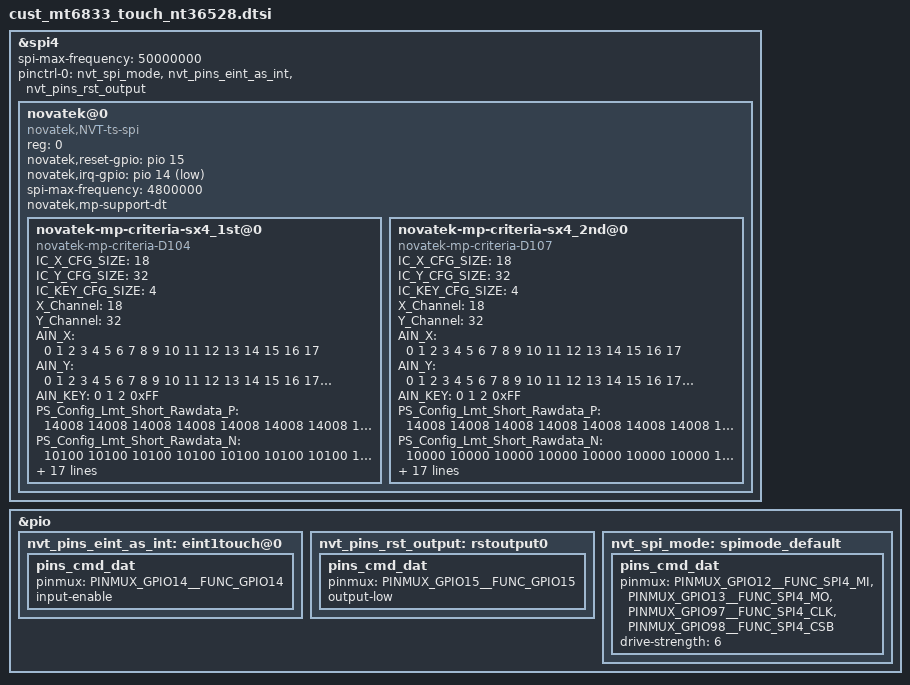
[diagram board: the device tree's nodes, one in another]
&spi4 {
    status = "okay";
	spi-max-frequency = <50000000>;
	pinctrl-names = "nvt_spi_mode";
	pinctrl-0 = <&nvt_spi_mode>,<&nvt_pins_eint_as_int>,<&nvt_pins_rst_output>;
	novatek@0 {
        status = "okay";
		compatible = "novatek,NVT-ts-spi";
		reg = <0>; //Same as CS ID
		novatek,reset-gpio = <&pio 15 0x00>;
		novatek,irq-gpio = <&pio 14 0x2001>;	
		spi-max-frequency = <4800000>;	//4800000,9600000,15000000,19200000

		novatek,mp-support-dt;

		novatek-mp-criteria-sx4_1st@0 {
			#address-cells = <1>;
			#size-cells = <0>;
			compatible = "novatek-mp-criteria-D104";

			/* MP Config */
			IC_X_CFG_SIZE = <18>;
			IC_Y_CFG_SIZE = <32>;
			IC_KEY_CFG_SIZE = <4>;
			X_Channel = <18>;
			Y_Channel = <32>;
			AIN_X = <0 1 2 3 4 5 6 7 8 9 10 11 12 13 14 15 16 17>;
			AIN_Y = <0 1 2 3 4 5 6 7 8 9 10 11 12 13 14 15 16 17 18 19 20 21 22 23 24 25 26 27 28 29 30 31>;
			AIN_KEY = <0 1 2 0xFF>;

			/* MP Criteria */
			PS_Config_Lmt_Short_Rawdata_P = <
				14008	14008	14008	14008	14008	14008	14008	14008	14008	14008	14008	14008	14008	14008	14008	14008	14008	14008
				14008	14008	14008	14008	14008	14008	14008	14008	14008	14008	14008	14008	14008	14008	14008	14008	14008	14008
				14008	14008	14008	14008	14008	14008	14008	14008	14008	14008	14008	14008	14008	14008	14008	14008	14008	14008
				14008	14008	14008	14008	14008	14008	14008	14008	14008	14008	14008	14008	14008	14008	14008	14008	14008	14008
				14008	14008	14008	14008	14008	14008	14008	14008	14008	14008	14008	14008	14008	14008	14008	14008	14008	14008
				14008	14008	14008	14008	14008	14008	14008	14008	14008	14008	14008	14008	14008	14008	14008	14008	14008	14008
				14008	14008	14008	14008	14008	14008	14008	14008	14008	14008	14008	14008	14008	14008	14008	14008	14008	14008
				14008	14008	14008	14008	14008	14008	14008	14008	14008	14008	14008	14008	14008	14008	14008	14008	14008	14008
				14008	14008	14008	14008	14008	14008	14008	14008	14008	14008	14008	14008	14008	14008	14008	14008	14008	14008
				14008	14008	14008	14008	14008	14008	14008	14008	14008	14008	14008	14008	14008	14008	14008	14008	14008	14008
				14008	14008	14008	14008	14008	14008	14008	14008	14008	14008	14008	14008	14008	14008	14008	14008	14008	14008
				14008	14008	14008	14008	14008	14008	14008	14008	14008	14008	14008	14008	14008	14008	14008	14008	14008	14008
				14008	14008	14008	14008	14008	14008	14008	14008	14008	14008	14008	14008	14008	14008	14008	14008	14008	14008
				14008	14008	14008	14008	14008	14008	14008	14008	14008	14008	14008	14008	14008	14008	14008	14008	14008	14008
				14008	14008	14008	14008	14008	14008	14008	14008	14008	14008	14008	14008	14008	14008	14008	14008	14008	14008
				14008	14008	14008	14008	14008	14008	14008	14008	14008	14008	14008	14008	14008	14008	14008	14008	14008	14008
				14008	14008	14008	14008	14008	14008	14008	14008	14008	14008	14008	14008	14008	14008	14008	14008	14008	14008
				14008	14008	14008	14008	14008	14008	14008	14008	14008	14008	14008	14008	14008	14008	14008	14008	14008	14008
				14008	14008	14008	14008	14008	14008	14008	14008	14008	14008	14008	14008	14008	14008	14008	14008	14008	14008
				14008	14008	14008	14008	14008	14008	14008	14008	14008	14008	14008	14008	14008	14008	14008	14008	14008	14008
				14008	14008	14008	14008	14008	14008	14008	14008	14008	14008	14008	14008	14008	14008	14008	14008	14008	14008
				14008	14008	14008	14008	14008	14008	14008	14008	14008	14008	14008	14008	14008	14008	14008	14008	14008	14008
				14008	14008	14008	14008	14008	14008	14008	14008	14008	14008	14008	14008	14008	14008	14008	14008	14008	14008
				14008	14008	14008	14008	14008	14008	14008	14008	14008	14008	14008	14008	14008	14008	14008	14008	14008	14008
				14008	14008	14008	14008	14008	14008	14008	14008	14008	14008	14008	14008	14008	14008	14008	14008	14008	14008
				14008	14008	14008	14008	14008	14008	14008	14008	14008	14008	14008	14008	14008	14008	14008	14008	14008	14008
				14008	14008	14008	14008	14008	14008	14008	14008	14008	14008	14008	14008	14008	14008	14008	14008	14008	14008
				14008	14008	14008	14008	14008	14008	14008	14008	14008	14008	14008	14008	14008	14008	14008	14008	14008	14008
				14008	14008	14008	14008	14008	14008	14008	14008	14008	14008	14008	14008	14008	14008	14008	14008	14008	14008
				14008	14008	14008	14008	14008	14008	14008	14008	14008	14008	14008	14008	14008	14008	14008	14008	14008	14008
				14008	14008	14008	14008	14008	14008	14008	14008	14008	14008	14008	14008	14008	14008	14008	14008	14008	14008
				14008	14008	14008	14008	14008	14008	14008	14008	14008	14008	14008	14008	14008	14008	14008	14008	14008	14008
				>;

			PS_Config_Lmt_Short_Rawdata_N = <
				10100	10100	10100	10100	10100	10100	10100	10100	10100	10100	10100	10100	10100	10100	10100	10100	10100	10100
				10100	10100	10100	10100	10100	10100	10100	10100	10100	10100	10100	10100	10100	10100	10100	10100	10100	10100
				10100	10100	10100	10100	10100	10100	10100	10100	10100	10100	10100	10100	10100	10100	10100	10100	10100	10100
				10100	10100	10100	10100	10100	10100	10100	10100	10100	10100	10100	10100	10100	10100	10100	10100	10100	10100
				10100	10100	10100	10100	10100	10100	10100	10100	10100	10100	10100	10100	10100	10100	10100	10100	10100	10100
				10100	10100	10100	10100	10100	10100	10100	10100	10100	10100	10100	10100	10100	10100	10100	10100	10100	10100
				10100	10100	10100	10100	10100	10100	10100	10100	10100	10100	10100	10100	10100	10100	10100	10100	10100	10100
				10100	10100	10100	10100	10100	10100	10100	10100	10100	10100	10100	10100	10100	10100	10100	10100	10100	10100
				10100	10100	10100	10100	10100	10100	10100	10100	10100	10100	10100	10100	10100	10100	10100	10100	10100	10100
				10100	10100	10100	10100	10100	10100	10100	10100	10100	10100	10100	10100	10100	10100	10100	10100	10100	10100
				10100	10100	10100	10100	10100	10100	10100	10100	10100	10100	10100	10100	10100	10100	10100	10100	10100	10100
				10100	10100	10100	10100	10100	10100	10100	10100	10100	10100	10100	10100	10100	10100	10100	10100	10100	10100
				10100	10100	10100	10100	10100	10100	10100	10100	10100	10100	10100	10100	10100	10100	10100	10100	10100	10100
				10100	10100	10100	10100	10100	10100	10100	10100	10100	10100	10100	10100	10100	10100	10100	10100	10100	10100
				10100	10100	10100	10100	10100	10100	10100	10100	10100	10100	10100	10100	10100	10100	10100	10100	10100	10100
				10100	10100	10100	10100	10100	10100	10100	10100	10100	10100	10100	10100	10100	10100	10100	10100	10100	10100
				10100	10100	10100	10100	10100	10100	10100	10100	10100	10100	10100	10100	10100	10100	10100	10100	10100	10100
				10100	10100	10100	10100	10100	10100	10100	10100	10100	10100	10100	10100	10100	10100	10100	10100	10100	10100
				10100	10100	10100	10100	10100	10100	10100	10100	10100	10100	10100	10100	10100	10100	10100	10100	10100	10100
				10100	10100	10100	10100	10100	10100	10100	10100	10100	10100	10100	10100	10100	10100	10100	10100	10100	10100
				10100	10100	10100	10100	10100	10100	10100	10100	10100	10100	10100	10100	10100	10100	10100	10100	10100	10100
				10100	10100	10100	10100	10100	10100	10100	10100	10100	10100	10100	10100	10100	10100	10100	10100	10100	10100
				10100	10100	10100	10100	10100	10100	10100	10100	10100	10100	10100	10100	10100	10100	10100	10100	10100	10100
				10100	10100	10100	10100	10100	10100	10100	10100	10100	10100	10100	10100	10100	10100	10100	10100	10100	10100
				10100	10100	10100	10100	10100	10100	10100	10100	10100	10100	10100	10100	10100	10100	10100	10100	10100	10100
				10100	10100	10100	10100	10100	10100	10100	10100	10100	10100	10100	10100	10100	10100	10100	10100	10100	10100
				10100	10100	10100	10100	10100	10100	10100	10100	10100	10100	10100	10100	10100	10100	10100	10100	10100	10100
				10100	10100	10100	10100	10100	10100	10100	10100	10100	10100	10100	10100	10100	10100	10100	10100	10100	10100
				10100	10100	10100	10100	10100	10100	10100	10100	10100	10100	10100	10100	10100	10100	10100	10100	10100	10100
				10100	10100	10100	10100	10100	10100	10100	10100	10100	10100	10100	10100	10100	10100	10100	10100	10100	10100
				10100	10100	10100	10100	10100	10100	10100	10100	10100	10100	10100	10100	10100	10100	10100	10100	10100	10100
				10100	10100	10100	10100	10100	10100	10100	10100	10100	10100	10100	10100	10100	10100	10100	10100	10100	10100
				>;

			PS_Config_Lmt_Open_Rawdata_P = <
				2699	2673	2589	2537	2470	2404	2369	2297	65535	65535	2071	2139	2159	2209	2255	2272	2331	2388
				2590	2594	2537	2468	2407	2355	2311	2279	2244	2332	2356	2381	2411	2449	2486	2519	2570	2619
				2800	2808	2752	2688	2628	2572	2528	2496	2463	2216	2234	2253	2288	2324	2358	2390	2436	2484
				2633	2657	2604	2538	2477	2425	2383	2349	2320	2379	2397	2419	2456	2492	2530	2566	2614	2661
				2782	2813	2750	2685	2619	2561	2519	2482	2456	2307	2327	2344	2377	2415	2450	2484	2530	2575
				2688	2730	2667	2603	2541	2486	2444	2408	2380	2475	2493	2514	2549	2590	2629	2670	2719	2762
				2806	2772	2724	2666	2596	2537	2503	2463	2423	2335	2359	2387	2411	2457	2498	2526	2569	2510
				2667	2628	2587	2530	2463	2404	2373	2334	2300	2519	2542	2575	2598	2649	2695	2727	2768	2727
				2870	2828	2782	2726	2656	2594	2565	2520	2486	2442	2467	2492	2517	2561	2605	2633	2674	2639
				2733	2688	2645	2586	2517	2457	2426	2383	2351	2572	2596	2628	2653	2699	2745	2782	2822	2801
				2975	2925	2873	2815	2745	2685	2647	2608	2572	2481	2502	2533	2552	2598	2647	2671	2717	2705
				2842	2790	2741	2682	2615	2558	2524	2484	2449	2727	2754	2786	2810	2856	2904	2934	2983	2982
				3060	3006	2953	2891	2827	2765	2726	2688	2643	2593	2615	2647	2667	2715	2759	2782	2829	2838
				2947	2901	2843	2780	2715	2654	2617	2580	2540	2705	2733	2762	2786	2834	2878	2909	2961	2976
				3156	3102	3042	2985	2916	2855	2822	2778	2740	2617	2646	2673	2702	2747	2790	2818	2869	2897
				3032	2982	2926	2866	2799	2740	2703	2661	2626	2797	2825	2855	2887	2932	2978	3016	3066	3102
				3259	3205	3143	3086	3016	2951	2915	2866	2832	2747	2773	2804	2828	2873	2915	2944	2995	3039
				3140	3087	3031	2969	2899	2841	2803	2755	2723	2877	2904	2939	2967	3013	3058	3091	3139	3184
				3366	3318	3258	3191	3122	3060	3016	2975	2933	2783	2803	2842	2866	2913	2962	2992	3041	3083
				3251	3202	3146	3081	3011	2955	2912	2874	2832	2979	3006	3037	3067	3111	3161	3192	3248	3300
				3487	3436	3371	3305	3231	3172	3125	3083	3034	2912	2940	2968	3000	3045	3090	3119	3171	3227
				3354	3304	3248	3179	3108	3044	3004	2958	2915	3105	3136	3171	3200	3254	3301	3340	3391	3444
				3625	3576	3510	3447	3371	3305	3263	3212	3171	3014	3049	3079	3109	3153	3199	3235	3290	3343
				3490	3438	3374	3308	3238	3177	3130	3086	3048	3209	3238	3270	3307	3354	3401	3444	3497	3552
				3723	3679	3608	3542	3468	3402	3356	3305	3263	3121	3147	3181	3209	3255	3308	3340	3405	3454
				3591	3553	3486	3417	3345	3282	3233	3188	3142	3296	3328	3359	3395	3441	3492	3532	3594	3644
				3695	3781	3706	3632	3559	3499	3447	3403	3353	3213	3240	3272	3308	3354	3399	3437	3503	3452
				3632	3721	3655	3581	3500	3440	3395	3343	3301	3396	3422	3464	3497	3545	3599	3640	3696	3618
				3842	3956	3879	3811	3734	3667	3620	3570	3522	3326	3356	3387	3424	3472	3520	3557	3619	3548
				3637	3762	3697	3623	3549	3485	3437	3385	3345	3510	3535	3574	3616	3665	3716	3759	3814	3717
				3871	4025	3956	3885	3812	3745	3697	3647	3604	3405	3433	3469	3503	3552	3604	3643	3702	3609
				3856	3928	3917	3842	3769	3704	3654	3606	3557	3583	3615	3653	3692	3742	3794	3836	3844	3815
				>;

			PS_Config_Lmt_Open_Rawdata_N = <
				1157	1145	1109	1087	1058	1030	1015	985	(-65535)	(-65535)	887	917	925	947	967	974	999	1024
				1110	1112	1087	1058	1031	1009	991	977	962	1000	1010	1021	1033	1049	1066	1079	1102	1123
				1200	1204	1180	1152	1126	1102	1084	1070	1055	950	958	965	980	996	1010	1024	1044	1064
				1129	1139	1116	1088	1061	1039	1021	1007	994	1019	1027	1037	1052	1068	1084	1100	1120	1141
				1192	1205	1178	1151	1123	1097	1079	1064	1052	989	997	1004	1019	1035	1050	1064	1084	1103
				1152	1170	1143	1115	1089	1066	1048	1032	1020	1061	1069	1078	1093	1110	1127	1144	1165	1184
				1202	1188	1168	1142	1112	1087	1073	1055	1039	1001	1011	1023	1033	1053	1070	1082	1101	1076
				1143	1126	1109	1084	1055	1030	1017	1000	986	1079	1090	1103	1114	1135	1155	1169	1186	1169
				1230	1212	1192	1168	1138	1112	1099	1080	1066	1046	1057	1068	1079	1097	1117	1129	1146	1131
				1171	1152	1133	1108	1079	1053	1040	1021	1007	1102	1112	1126	1137	1157	1177	1192	1210	1201
				1275	1253	1231	1207	1177	1151	1135	1118	1102	1063	1072	1085	1094	1114	1135	1145	1165	1159
				1218	1196	1175	1150	1121	1096	1082	1064	1049	1169	1180	1194	1204	1224	1244	1258	1279	1278
				1312	1288	1265	1239	1211	1185	1168	1152	1133	1111	1121	1135	1143	1163	1183	1192	1213	1216
				1263	1243	1219	1192	1163	1138	1121	1106	1088	1159	1171	1184	1194	1214	1234	1247	1269	1276
				1352	1330	1304	1279	1250	1223	1210	1190	1174	1121	1134	1145	1158	1177	1196	1208	1229	1241
				1300	1278	1254	1228	1199	1174	1159	1141	1126	1199	1211	1223	1237	1256	1276	1292	1314	1330
				1397	1373	1347	1322	1292	1265	1249	1228	1214	1177	1189	1202	1212	1231	1249	1262	1283	1303
				1346	1323	1299	1273	1243	1217	1201	1181	1167	1233	1244	1259	1271	1291	1310	1325	1345	1364
				1442	1422	1396	1367	1338	1312	1292	1275	1257	1193	1201	1218	1228	1249	1270	1282	1303	1321
				1393	1372	1348	1321	1291	1267	1248	1232	1214	1277	1288	1301	1315	1333	1355	1368	1392	1414
				1495	1472	1445	1417	1385	1360	1339	1321	1300	1248	1260	1272	1286	1305	1324	1337	1359	1383
				1438	1416	1392	1363	1332	1304	1288	1268	1249	1331	1344	1359	1372	1394	1415	1432	1453	1476
				1553	1532	1504	1477	1445	1417	1399	1376	1359	1292	1307	1319	1333	1351	1371	1387	1410	1433
				1496	1474	1446	1418	1388	1361	1342	1322	1306	1375	1388	1402	1417	1438	1457	1476	1499	1522
				1595	1577	1546	1518	1486	1458	1438	1417	1399	1337	1349	1363	1375	1395	1418	1432	1459	1480
				1539	1523	1494	1465	1433	1406	1385	1366	1346	1412	1426	1439	1455	1475	1496	1514	1540	1562
				1583	1621	1588	1556	1525	1499	1477	1459	1437	1377	1388	1402	1418	1438	1457	1473	1501	1480
				1556	1595	1567	1535	1500	1474	1455	1433	1415	1456	1466	1484	1499	1519	1543	1560	1584	1550
				1646	1696	1663	1633	1600	1571	1552	1530	1510	1426	1438	1451	1468	1488	1508	1525	1551	1520
				1559	1612	1585	1553	1521	1493	1473	1451	1433	1504	1515	1532	1550	1571	1592	1611	1634	1593
				1659	1725	1696	1665	1634	1605	1585	1563	1544	1459	1471	1487	1501	1522	1544	1561	1586	1547
				1652	1684	1679	1646	1615	1588	1566	1546	1525	1535	1549	1565	1582	1604	1626	1644	1648	1635
				>;

			PS_Config_Lmt_FW_Rawdata_P = <
				1123	1119	1123	1124	1121	1119	1119	1123	65535	65535	1117	1117	1120	1121	1117	1119	1123	1119
				1121	1123	1121	1120	1121	1121	1123	1124	1126	1121	1123	1124	1121	1123	1121	1120	1119	1121
				1116	1121	1119	1121	1124	1128	1128	1128	1126	1119	1124	1124	1123	1124	1119	1123	1126	1123
				1123	1120	1123	1121	1120	1120	1121	1123	1119	1123	1119	1120	1121	1123	1119	1121	1123	1120
				1120	1124	1120	1121	1126	1123	1119	1119	1119	1119	1119	1119	1124	1127	1120	1120	1117	1117
				1117	1126	1120	1119	1121	1123	1126	1126	1123	1123	1119	1120	1119	1120	1121	1117	1126	1119
				1121	1123	1119	1126	1117	1119	1117	1120	1121	1121	1114	1121	1116	1119	1123	1121	1124	1117
				1121	1119	1120	1120	1123	1119	1119	1123	1119	1123	1121	1124	1123	1119	1121	1124	1126	1117
				1119	1120	1123	1121	1117	1119	1117	1119	1117	1121	1119	1120	1121	1121	1121	1120	1120	1121
				1123	1119	1113	1123	1119	1121	1121	1120	1119	1120	1119	1121	1121	1120	1119	1117	1116	1119
				1123	1120	1121	1123	1119	1121	1117	1119	1123	1119	1123	1124	1121	1121	1124	1119	1123	1114
				1119	1123	1123	1123	1119	1119	1120	1121	1123	1119	1117	1121	1120	1123	1121	1121	1123	1121
				1121	1121	1119	1121	1126	1123	1121	1120	1120	1119	1121	1126	1126	1127	1127	1121	1120	1119
				1123	1120	1119	1121	1121	1121	1119	1119	1121	1119	1119	1120	1120	1120	1121	1119	1117	1124
				1116	1123	1119	1123	1120	1119	1123	1127	1120	1119	1124	1124	1123	1124	1123	1121	1121	1119
				1123	1119	1117	1124	1126	1124	1123	1119	1120	1121	1117	1119	1120	1117	1120	1123	1121	1120
				1124	1124	1121	1121	1120	1119	1121	1124	1119	1117	1124	1123	1124	1123	1121	1120	1121	1119
				1121	1117	1121	1119	1116	1114	1116	1119	1127	1123	1120	1117	1119	1120	1121	1121	1120	1120
				1120	1121	1119	1117	1120	1121	1121	1117	1124	1120	1120	1119	1120	1121	1117	1119	1120	1121
				1127	1120	1121	1123	1124	1123	1120	1124	1117	1120	1124	1124	1124	1126	1120	1117	1124	1120
				1116	1123	1117	1127	1124	1124	1124	1127	1114	1117	1127	1127	1123	1126	1123	1117	1119	1117
				1121	1120	1116	1121	1120	1119	1120	1117	1126	1119	1121	1121	1124	1124	1121	1120	1116	1120
				1120	1123	1123	1120	1119	1117	1121	1120	1119	1120	1119	1120	1119	1121	1121	1117	1121	1121
				1121	1123	1116	1121	1123	1121	1121	1121	1120	1123	1120	1120	1121	1121	1120	1123	1117	1121
				1127	1120	1123	1116	1116	1117	1119	1119	1121	1119	1123	1120	1119	1119	1120	1119	1120	1114
				1121	1119	1121	1117	1119	1119	1123	1119	1120	1120	1123	1119	1123	1123	1120	1121	1121	1120
				1126	1119	1126	1120	1114	1116	1114	1116	1124	1120	1121	1124	1117	1119	1120	1121	1120	1123
				1123	1120	1121	1119	1120	1120	1119	1116	1119	1120	1117	1119	1120	1124	1124	1116	1123	1116
				1121	1121	1119	1121	1121	1120	1121	1120	1121	1120	1120	1121	1123	1124	1123	1123	1120	1120
				1120	1126	1124	1121	1123	1120	1120	1119	1120	1121	1123	1123	1123	1121	1120	1121	1124	1120
				1113	1120	1120	1116	1119	1120	1121	1120	1121	1120	1116	1119	1120	1123	1121	1120	1119	1123
				1120	1121	1120	1123	1120	1119	1119	1119	1123	1121	1119	1119	1119	1120	1119	1120	1117	1121
				>;

			PS_Config_Lmt_FW_Rawdata_N = <
				481	479	481	482	481	479	479	481	(-65535)	(-65535)	479	479	480	481	479	479	481	479
				481	481	481	480	481	481	481	482	482	481	481	482	481	481	481	480	479	481
				478	481	479	481	482	484	484	484	482	479	482	482	481	482	479	481	482	481
				481	480	481	481	480	480	481	481	479	481	479	480	481	481	479	481	481	480
				480	482	480	481	482	481	479	479	479	479	479	479	482	483	480	480	479	479
				479	482	480	479	481	481	482	482	481	481	479	480	479	480	481	479	482	479
				481	481	479	482	479	479	479	480	481	481	478	481	478	479	481	481	482	479
				481	479	480	480	481	479	479	481	479	481	481	482	481	479	481	482	482	479
				479	480	481	481	479	479	479	479	479	481	479	480	481	481	481	480	480	481
				481	479	477	481	479	481	481	480	479	480	479	481	481	480	479	479	478	479
				481	480	481	481	479	481	479	479	481	479	481	482	481	481	482	479	481	478
				479	481	481	481	479	479	480	481	481	479	479	481	480	481	481	481	481	481
				481	481	479	481	482	481	481	480	480	479	481	482	482	483	483	481	480	479
				481	480	479	481	481	481	479	479	481	479	479	480	480	480	481	479	479	482
				478	481	479	481	480	479	481	483	480	479	482	482	481	482	481	481	481	479
				481	479	479	482	482	482	481	479	480	481	479	479	480	479	480	481	481	480
				482	482	481	481	480	479	481	482	479	479	482	481	482	481	481	480	481	479
				481	479	481	479	478	478	478	479	483	481	480	479	479	480	481	481	480	480
				480	481	479	479	480	481	481	479	482	480	480	479	480	481	479	479	480	481
				483	480	481	481	482	481	480	482	479	480	482	482	482	482	480	479	482	480
				478	481	479	483	482	482	482	483	478	479	483	483	481	482	481	479	479	479
				481	480	478	481	480	479	480	479	482	479	481	481	482	482	481	480	478	480
				480	481	481	480	479	479	481	480	479	480	479	480	479	481	481	479	481	481
				481	481	478	481	481	481	481	481	480	481	480	480	481	481	480	481	479	481
				483	480	481	478	478	479	479	479	481	479	481	480	479	479	480	479	480	478
				481	479	481	479	479	479	481	479	480	480	481	479	481	481	480	481	481	480
				482	479	482	480	478	478	478	478	482	480	481	482	479	479	480	481	480	481
				481	480	481	479	480	480	479	478	479	480	479	479	480	482	482	478	481	478
				481	481	479	481	481	480	481	480	481	480	480	481	481	482	481	481	480	480
				480	482	482	481	481	480	480	479	480	481	481	481	481	481	480	481	482	480
				477	480	480	478	479	480	481	480	481	480	478	479	480	481	481	480	479	481
				480	481	480	481	480	479	479	479	481	481	479	479	479	480	479	480	479	481
				>;

			PS_Config_Lmt_FW_CC_P = <
				145	139	134	134	134	135	135	130	65535	65535	127	134	134	132	131	131	138	144
				155	149	144	139	139	139	139	139	141	141	139	138	139	139	139	142	149	155
				155	149	144	141	139	139	139	139	142	142	139	139	141	141	141	144	150	156
				156	149	144	141	141	141	139	139	142	142	139	139	141	141	141	144	149	156
				156	150	145	142	141	141	141	141	144	144	141	142	142	142	142	145	150	157
				157	153	146	144	144	144	142	142	145	144	142	142	142	144	144	146	152	157
				157	150	146	139	138	138	138	138	139	141	139	139	139	139	141	146	153	157
				157	150	145	138	138	137	137	138	138	139	138	138	138	138	139	145	152	156
				157	149	145	138	138	137	138	138	138	141	139	139	139	139	139	146	152	157
				157	150	145	138	138	137	138	138	138	138	138	138	137	138	138	145	149	156
				159	150	145	139	138	138	138	138	139	139	139	139	138	139	139	145	152	159
				157	150	145	138	138	138	138	139	139	142	142	141	141	141	141	146	153	159
				157	150	145	139	138	138	139	139	141	144	142	142	141	141	142	146	153	159
				157	150	145	139	139	139	139	139	141	142	141	141	139	139	139	145	152	157
				160	153	145	141	141	141	141	141	142	142	141	141	141	141	141	145	152	160
				159	152	145	141	141	141	141	142	142	144	142	142	141	142	142	146	152	159
				159	153	146	142	142	142	142	142	144	145	144	144	144	144	144	148	155	161
				160	153	146	142	142	142	142	142	144	144	144	142	142	144	144	146	155	160
				160	153	146	144	144	144	142	144	144	145	145	144	144	145	145	148	156	160
				161	155	146	144	144	144	144	144	145	145	144	144	144	144	144	148	155	161
				161	155	148	145	144	144	145	145	146	146	145	145	145	145	145	149	156	163
				163	156	149	145	145	145	145	145	146	146	145	145	145	145	145	149	156	163
				166	159	152	148	148	148	148	148	149	149	148	148	148	148	148	153	160	166
				166	159	152	148	148	148	148	148	149	150	148	148	148	149	149	153	160	167
				167	160	153	149	149	149	149	149	150	152	149	149	149	149	149	155	160	167
				167	161	155	150	149	149	149	149	152	150	149	149	149	149	149	153	160	167
				164	160	155	150	149	149	149	149	152	152	149	149	149	149	150	155	160	164
				164	161	155	150	149	149	149	149	152	152	149	149	149	149	150	155	160	164
				167	161	155	152	150	150	150	150	153	152	150	150	150	150	150	155	161	166
				163	160	153	149	149	149	149	149	150	152	149	149	149	150	150	155	160	164
				164	160	153	150	149	149	149	149	150	152	150	150	150	150	150	155	161	164
				166	161	156	152	152	152	150	150	153	153	150	150	150	150	150	155	160	164
				>;

			PS_Config_Lmt_FW_CC_N = <
				65	63	60	60	60	61	61	58	(-65535)	(-65535)	57	60	60	60	59	59	62	64
				69	67	64	63	63	63	63	63	63	63	63	62	63	63	63	64	67	69
				69	67	64	63	63	63	63	63	64	64	63	63	63	63	63	64	68	70
				70	67	64	63	63	63	63	63	64	64	63	63	63	63	63	64	67	70
				70	68	65	64	63	63	63	63	64	64	63	64	64	64	64	65	68	71
				71	69	66	64	64	64	64	64	65	64	64	64	64	64	64	66	68	71
				71	68	66	63	62	62	62	62	63	63	63	63	63	63	63	66	69	71
				71	68	65	62	62	61	61	62	62	63	62	62	62	62	63	65	68	70
				71	67	65	62	62	61	62	62	62	63	63	63	63	63	63	66	68	71
				71	68	65	62	62	61	62	62	62	62	62	62	61	62	62	65	67	70
				71	68	65	63	62	62	62	62	63	63	63	63	62	63	63	65	68	71
				71	68	65	62	62	62	62	63	63	64	64	63	63	63	63	66	69	71
				71	68	65	63	62	62	63	63	63	64	64	64	63	63	64	66	69	71
				71	68	65	63	63	63	63	63	63	64	63	63	63	63	63	65	68	71
				72	69	65	63	63	63	63	63	64	64	63	63	63	63	63	65	68	72
				71	68	65	63	63	63	63	64	64	64	64	64	63	64	64	66	68	71
				71	69	66	64	64	64	64	64	64	65	64	64	64	64	64	66	69	73
				72	69	66	64	64	64	64	64	64	64	64	64	64	64	64	66	69	72
				72	69	66	64	64	64	64	64	64	65	65	64	64	65	65	66	70	72
				73	69	66	64	64	64	64	64	65	65	64	64	64	64	64	66	69	73
				73	69	66	65	64	64	65	65	66	66	65	65	65	65	65	67	70	73
				73	70	67	65	65	65	65	65	66	66	65	65	65	65	65	67	70	73
				74	71	68	66	66	66	66	66	67	67	66	66	66	66	66	69	72	74
				74	71	68	66	66	66	66	66	67	68	66	66	66	67	67	69	72	75
				75	72	69	67	67	67	67	67	68	68	67	67	67	67	67	69	72	75
				75	73	69	68	67	67	67	67	68	68	67	67	67	67	67	69	72	75
				74	72	69	68	67	67	67	67	68	68	67	67	67	67	68	69	72	74
				74	73	69	68	67	67	67	67	68	68	67	67	67	67	68	69	72	74
				75	73	69	68	68	68	68	68	69	68	68	68	68	68	68	69	73	74
				73	72	69	67	67	67	67	67	68	68	67	67	67	68	68	69	72	74
				74	72	69	68	67	67	67	67	68	68	68	68	68	68	68	69	73	74
				74	73	70	68	68	68	68	68	69	69	68	68	68	68	68	69	72	74
				>;

			PS_Config_Lmt_FW_Diff_P = <
				50	50	50	50	50	50	50	50	65535	65535	50	50	50	50	50	50	50	50
				50	50	50	50	50	50	50	50	50	50	50	50	50	50	50	50	50	50
				50	50	50	50	50	50	50	50	50	50	50	50	50	50	50	50	50	50
				50	50	50	50	50	50	50	50	50	50	50	50	50	50	50	50	50	50
				50	50	50	50	50	50	50	50	50	50	50	50	50	50	50	50	50	50
				50	50	50	50	50	50	50	50	50	50	50	50	50	50	50	50	50	50
				50	50	50	50	50	50	50	50	50	50	50	50	50	50	50	50	50	50
				50	50	50	50	50	50	50	50	50	50	50	50	50	50	50	50	50	50
				50	50	50	50	50	50	50	50	50	50	50	50	50	50	50	50	50	50
				50	50	50	50	50	50	50	50	50	50	50	50	50	50	50	50	50	50
				50	50	50	50	50	50	50	50	50	50	50	50	50	50	50	50	50	50
				50	50	50	50	50	50	50	50	50	50	50	50	50	50	50	50	50	50
				50	50	50	50	50	50	50	50	50	50	50	50	50	50	50	50	50	50
				50	50	50	50	50	50	50	50	50	50	50	50	50	50	50	50	50	50
				50	50	50	50	50	50	50	50	50	50	50	50	50	50	50	50	50	50
				50	50	50	50	50	50	50	50	50	50	50	50	50	50	50	50	50	50
				50	50	50	50	50	50	50	50	50	50	50	50	50	50	50	50	50	50
				50	50	50	50	50	50	50	50	50	50	50	50	50	50	50	50	50	50
				50	50	50	50	50	50	50	50	50	50	50	50	50	50	50	50	50	50
				50	50	50	50	50	50	50	50	50	50	50	50	50	50	50	50	50	50
				50	50	50	50	50	50	50	50	50	50	50	50	50	50	50	50	50	50
				50	50	50	50	50	50	50	50	50	50	50	50	50	50	50	50	50	50
				50	50	50	50	50	50	50	50	50	50	50	50	50	50	50	50	50	50
				50	50	50	50	50	50	50	50	50	50	50	50	50	50	50	50	50	50
				50	50	50	50	50	50	50	50	50	50	50	50	50	50	50	50	50	50
				50	50	50	50	50	50	50	50	50	50	50	50	50	50	50	50	50	50
				50	50	50	50	50	50	50	50	50	50	50	50	50	50	50	50	50	50
				50	50	50	50	50	50	50	50	50	50	50	50	50	50	50	50	50	50
				50	50	50	50	50	50	50	50	50	50	50	50	50	50	50	50	50	50
				50	50	50	50	50	50	50	50	50	50	50	50	50	50	50	50	50	50
				50	50	50	50	50	50	50	50	50	50	50	50	50	50	50	50	50	50
				50	50	50	50	50	50	50	50	50	50	50	50	50	50	50	50	50	50
				>;

			PS_Config_Lmt_FW_Diff_N = <
				(-50)	(-50)	(-50)	(-50)	(-50)	(-50)	(-50)	(-50)	(-65535)	(-65535)	(-50)	(-50)	(-50)	(-50)	(-50)	(-50)	(-50)	(-50)
				(-50)	(-50)	(-50)	(-50)	(-50)	(-50)	(-50)	(-50)	(-50)	(-50)	(-50)	(-50)	(-50)	(-50)	(-50)	(-50)	(-50)	(-50)
				(-50)	(-50)	(-50)	(-50)	(-50)	(-50)	(-50)	(-50)	(-50)	(-50)	(-50)	(-50)	(-50)	(-50)	(-50)	(-50)	(-50)	(-50)
				(-50)	(-50)	(-50)	(-50)	(-50)	(-50)	(-50)	(-50)	(-50)	(-50)	(-50)	(-50)	(-50)	(-50)	(-50)	(-50)	(-50)	(-50)
				(-50)	(-50)	(-50)	(-50)	(-50)	(-50)	(-50)	(-50)	(-50)	(-50)	(-50)	(-50)	(-50)	(-50)	(-50)	(-50)	(-50)	(-50)
				(-50)	(-50)	(-50)	(-50)	(-50)	(-50)	(-50)	(-50)	(-50)	(-50)	(-50)	(-50)	(-50)	(-50)	(-50)	(-50)	(-50)	(-50)
				(-50)	(-50)	(-50)	(-50)	(-50)	(-50)	(-50)	(-50)	(-50)	(-50)	(-50)	(-50)	(-50)	(-50)	(-50)	(-50)	(-50)	(-50)
				(-50)	(-50)	(-50)	(-50)	(-50)	(-50)	(-50)	(-50)	(-50)	(-50)	(-50)	(-50)	(-50)	(-50)	(-50)	(-50)	(-50)	(-50)
				(-50)	(-50)	(-50)	(-50)	(-50)	(-50)	(-50)	(-50)	(-50)	(-50)	(-50)	(-50)	(-50)	(-50)	(-50)	(-50)	(-50)	(-50)
				(-50)	(-50)	(-50)	(-50)	(-50)	(-50)	(-50)	(-50)	(-50)	(-50)	(-50)	(-50)	(-50)	(-50)	(-50)	(-50)	(-50)	(-50)
				(-50)	(-50)	(-50)	(-50)	(-50)	(-50)	(-50)	(-50)	(-50)	(-50)	(-50)	(-50)	(-50)	(-50)	(-50)	(-50)	(-50)	(-50)
				(-50)	(-50)	(-50)	(-50)	(-50)	(-50)	(-50)	(-50)	(-50)	(-50)	(-50)	(-50)	(-50)	(-50)	(-50)	(-50)	(-50)	(-50)
				(-50)	(-50)	(-50)	(-50)	(-50)	(-50)	(-50)	(-50)	(-50)	(-50)	(-50)	(-50)	(-50)	(-50)	(-50)	(-50)	(-50)	(-50)
				(-50)	(-50)	(-50)	(-50)	(-50)	(-50)	(-50)	(-50)	(-50)	(-50)	(-50)	(-50)	(-50)	(-50)	(-50)	(-50)	(-50)	(-50)
				(-50)	(-50)	(-50)	(-50)	(-50)	(-50)	(-50)	(-50)	(-50)	(-50)	(-50)	(-50)	(-50)	(-50)	(-50)	(-50)	(-50)	(-50)
				(-50)	(-50)	(-50)	(-50)	(-50)	(-50)	(-50)	(-50)	(-50)	(-50)	(-50)	(-50)	(-50)	(-50)	(-50)	(-50)	(-50)	(-50)
				(-50)	(-50)	(-50)	(-50)	(-50)	(-50)	(-50)	(-50)	(-50)	(-50)	(-50)	(-50)	(-50)	(-50)	(-50)	(-50)	(-50)	(-50)
				(-50)	(-50)	(-50)	(-50)	(-50)	(-50)	(-50)	(-50)	(-50)	(-50)	(-50)	(-50)	(-50)	(-50)	(-50)	(-50)	(-50)	(-50)
				(-50)	(-50)	(-50)	(-50)	(-50)	(-50)	(-50)	(-50)	(-50)	(-50)	(-50)	(-50)	(-50)	(-50)	(-50)	(-50)	(-50)	(-50)
				(-50)	(-50)	(-50)	(-50)	(-50)	(-50)	(-50)	(-50)	(-50)	(-50)	(-50)	(-50)	(-50)	(-50)	(-50)	(-50)	(-50)	(-50)
				(-50)	(-50)	(-50)	(-50)	(-50)	(-50)	(-50)	(-50)	(-50)	(-50)	(-50)	(-50)	(-50)	(-50)	(-50)	(-50)	(-50)	(-50)
				(-50)	(-50)	(-50)	(-50)	(-50)	(-50)	(-50)	(-50)	(-50)	(-50)	(-50)	(-50)	(-50)	(-50)	(-50)	(-50)	(-50)	(-50)
				(-50)	(-50)	(-50)	(-50)	(-50)	(-50)	(-50)	(-50)	(-50)	(-50)	(-50)	(-50)	(-50)	(-50)	(-50)	(-50)	(-50)	(-50)
				(-50)	(-50)	(-50)	(-50)	(-50)	(-50)	(-50)	(-50)	(-50)	(-50)	(-50)	(-50)	(-50)	(-50)	(-50)	(-50)	(-50)	(-50)
				(-50)	(-50)	(-50)	(-50)	(-50)	(-50)	(-50)	(-50)	(-50)	(-50)	(-50)	(-50)	(-50)	(-50)	(-50)	(-50)	(-50)	(-50)
				(-50)	(-50)	(-50)	(-50)	(-50)	(-50)	(-50)	(-50)	(-50)	(-50)	(-50)	(-50)	(-50)	(-50)	(-50)	(-50)	(-50)	(-50)
				(-50)	(-50)	(-50)	(-50)	(-50)	(-50)	(-50)	(-50)	(-50)	(-50)	(-50)	(-50)	(-50)	(-50)	(-50)	(-50)	(-50)	(-50)
				(-50)	(-50)	(-50)	(-50)	(-50)	(-50)	(-50)	(-50)	(-50)	(-50)	(-50)	(-50)	(-50)	(-50)	(-50)	(-50)	(-50)	(-50)
				(-50)	(-50)	(-50)	(-50)	(-50)	(-50)	(-50)	(-50)	(-50)	(-50)	(-50)	(-50)	(-50)	(-50)	(-50)	(-50)	(-50)	(-50)
				(-50)	(-50)	(-50)	(-50)	(-50)	(-50)	(-50)	(-50)	(-50)	(-50)	(-50)	(-50)	(-50)	(-50)	(-50)	(-50)	(-50)	(-50)
				(-50)	(-50)	(-50)	(-50)	(-50)	(-50)	(-50)	(-50)	(-50)	(-50)	(-50)	(-50)	(-50)	(-50)	(-50)	(-50)	(-50)	(-50)
				(-50)	(-50)	(-50)	(-50)	(-50)	(-50)	(-50)	(-50)	(-50)	(-50)	(-50)	(-50)	(-50)	(-50)	(-50)	(-50)	(-50)	(-50)
				>;

			PS_Config_Diff_Test_Frame = <50>;
		};

		novatek-mp-criteria-sx4_2nd@0 {
			#address-cells = <1>;
			#size-cells = <0>;
			compatible = "novatek-mp-criteria-D107";

			/* MP Config */
			IC_X_CFG_SIZE = <18>;
			IC_Y_CFG_SIZE = <32>;
			IC_KEY_CFG_SIZE = <4>;
			X_Channel = <18>;
			Y_Channel = <32>;
			AIN_X = <0 1 2 3 4 5 6 7 8 9 10 11 12 13 14 15 16 17>;
			AIN_Y = <0 1 2 3 4 5 6 7 8 9 10 11 12 13 14 15 16 17 18 19 20 21 22 23 24 25 26 27 28 29 30 31>;
			AIN_KEY = <0 1 2 0xFF>;

			/* MP Criteria */
			PS_Config_Lmt_Short_Rawdata_P = <
				14008 14008 14008 14008 14008 14008 14008 14008 14008 14008 14008 14008 14008 14008 14008 14008 14008 14008
				14008 14008 14008 14008 14008 14008 14008 14008 14008 14008 14008 14008 14008 14008 14008 14008 14008 14008
				14008 14008 14008 14008 14008 14008 14008 14008 14008 14008 14008 14008 14008 14008 14008 14008 14008 14008
				14008 14008 14008 14008 14008 14008 14008 14008 14008 14008 14008 14008 14008 14008 14008 14008 14008 14008
				14008 14008 14008 14008 14008 14008 14008 14008 14008 14008 14008 14008 14008 14008 14008 14008 14008 14008
				14008 14008 14008 14008 14008 14008 14008 14008 14008 14008 14008 14008 14008 14008 14008 14008 14008 14008
				14008 14008 14008 14008 14008 14008 14008 14008 14008 14008 14008 14008 14008 14008 14008 14008 14008 14008
				14008 14008 14008 14008 14008 14008 14008 14008 14008 14008 14008 14008 14008 14008 14008 14008 14008 14008
				14008 14008 14008 14008 14008 14008 14008 14008 14008 14008 14008 14008 14008 14008 14008 14008 14008 14008
				14008 14008 14008 14008 14008 14008 14008 14008 14008 14008 14008 14008 14008 14008 14008 14008 14008 14008
				14008 14008 14008 14008 14008 14008 14008 14008 14008 14008 14008 14008 14008 14008 14008 14008 14008 14008
				14008 14008 14008 14008 14008 14008 14008 14008 14008 14008 14008 14008 14008 14008 14008 14008 14008 14008
				14008 14008 14008 14008 14008 14008 14008 14008 14008 14008 14008 14008 14008 14008 14008 14008 14008 14008
				14008 14008 14008 14008 14008 14008 14008 14008 14008 14008 14008 14008 14008 14008 14008 14008 14008 14008
				14008 14008 14008 14008 14008 14008 14008 14008 14008 14008 14008 14008 14008 14008 14008 14008 14008 14008
				14008 14008 14008 14008 14008 14008 14008 14008 14008 14008 14008 14008 14008 14008 14008 14008 14008 14008
				14008 14008 14008 14008 14008 14008 14008 14008 14008 14008 14008 14008 14008 14008 14008 14008 14008 14008
				14008 14008 14008 14008 14008 14008 14008 14008 14008 14008 14008 14008 14008 14008 14008 14008 14008 14008
				14008 14008 14008 14008 14008 14008 14008 14008 14008 14008 14008 14008 14008 14008 14008 14008 14008 14008
				14008 14008 14008 14008 14008 14008 14008 14008 14008 14008 14008 14008 14008 14008 14008 14008 14008 14008
				14008 14008 14008 14008 14008 14008 14008 14008 14008 14008 14008 14008 14008 14008 14008 14008 14008 14008
				14008 14008 14008 14008 14008 14008 14008 14008 14008 14008 14008 14008 14008 14008 14008 14008 14008 14008
				14008 14008 14008 14008 14008 14008 14008 14008 14008 14008 14008 14008 14008 14008 14008 14008 14008 14008
				14008 14008 14008 14008 14008 14008 14008 14008 14008 14008 14008 14008 14008 14008 14008 14008 14008 14008
				14008 14008 14008 14008 14008 14008 14008 14008 14008 14008 14008 14008 14008 14008 14008 14008 14008 14008
				14008 14008 14008 14008 14008 14008 14008 14008 14008 14008 14008 14008 14008 14008 14008 14008 14008 14008
				14008 14008 14008 14008 14008 14008 14008 14008 14008 14008 14008 14008 14008 14008 14008 14008 14008 14008
				14008 14008 14008 14008 14008 14008 14008 14008 14008 14008 14008 14008 14008 14008 14008 14008 14008 14008
				14008 14008 14008 14008 14008 14008 14008 14008 14008 14008 14008 14008 14008 14008 14008 14008 14008 14008
				14008 14008 14008 14008 14008 14008 14008 14008 14008 14008 14008 14008 14008 14008 14008 14008 14008 14008
				14008 14008 14008 14008 14008 14008 14008 14008 14008 14008 14008 14008 14008 14008 14008 14008 14008 14008
				14008 14008 14008 14008 14008 14008 14008 14008 14008 14008 14008 14008 14008 14008 14008 14008 14008 14008
				>;

			PS_Config_Lmt_Short_Rawdata_N = <
				10000 10000 10000 10000 10000 10000 10000 10000 10000 10000 10000 10000 10000 10000 10000 10000 10000 10000
				10000 10000 10000 10000 10000 10000 10000 10000 10000 10000 10000 10000 10000 10000 10000 10000 10000 10000
				10000 10000 10000 10000 10000 10000 10000 10000 10000 10000 10000 10000 10000 10000 10000 10000 10000 10000
				10000 10000 10000 10000 10000 10000 10000 10000 10000 10000 10000 10000 10000 10000 10000 10000 10000 10000
				10000 10000 10000 10000 10000 10000 10000 10000 10000 10000 10000 10000 10000 10000 10000 10000 10000 10000
				10000 10000 10000 10000 10000 10000 10000 10000 10000 10000 10000 10000 10000 10000 10000 10000 10000 10000
				10000 10000 10000 10000 10000 10000 10000 10000 10000 10000 10000 10000 10000 10000 10000 10000 10000 10000
				10000 10000 10000 10000 10000 10000 10000 10000 10000 10000 10000 10000 10000 10000 10000 10000 10000 10000
				10000 10000 10000 10000 10000 10000 10000 10000 10000 10000 10000 10000 10000 10000 10000 10000 10000 10000
				10000 10000 10000 10000 10000 10000 10000 10000 10000 10000 10000 10000 10000 10000 10000 10000 10000 10000
				10000 10000 10000 10000 10000 10000 10000 10000 10000 10000 10000 10000 10000 10000 10000 10000 10000 10000
				10000 10000 10000 10000 10000 10000 10000 10000 10000 10000 10000 10000 10000 10000 10000 10000 10000 10000
				10000 10000 10000 10000 10000 10000 10000 10000 10000 10000 10000 10000 10000 10000 10000 10000 10000 10000
				10000 10000 10000 10000 10000 10000 10000 10000 10000 10000 10000 10000 10000 10000 10000 10000 10000 10000
				10000 10000 10000 10000 10000 10000 10000 10000 10000 10000 10000 10000 10000 10000 10000 10000 10000 10000
				10000 10000 10000 10000 10000 10000 10000 10000 10000 10000 10000 10000 10000 10000 10000 10000 10000 10000
				10000 10000 10000 10000 10000 10000 10000 10000 10000 10000 10000 10000 10000 10000 10000 10000 10000 10000
				10000 10000 10000 10000 10000 10000 10000 10000 10000 10000 10000 10000 10000 10000 10000 10000 10000 10000
				10000 10000 10000 10000 10000 10000 10000 10000 10000 10000 10000 10000 10000 10000 10000 10000 10000 10000
				10000 10000 10000 10000 10000 10000 10000 10000 10000 10000 10000 10000 10000 10000 10000 10000 10000 10000
				10000 10000 10000 10000 10000 10000 10000 10000 10000 10000 10000 10000 10000 10000 10000 10000 10000 10000
				10000 10000 10000 10000 10000 10000 10000 10000 10000 10000 10000 10000 10000 10000 10000 10000 10000 10000
				10000 10000 10000 10000 10000 10000 10000 10000 10000 10000 10000 10000 10000 10000 10000 10000 10000 10000
				10000 10000 10000 10000 10000 10000 10000 10000 10000 10000 10000 10000 10000 10000 10000 10000 10000 10000
				10000 10000 10000 10000 10000 10000 10000 10000 10000 10000 10000 10000 10000 10000 10000 10000 10000 10000
				10000 10000 10000 10000 10000 10000 10000 10000 10000 10000 10000 10000 10000 10000 10000 10000 10000 10000
				10000 10000 10000 10000 10000 10000 10000 10000 10000 10000 10000 10000 10000 10000 10000 10000 10000 10000
				10000 10000 10000 10000 10000 10000 10000 10000 10000 10000 10000 10000 10000 10000 10000 10000 10000 10000
				10000 10000 10000 10000 10000 10000 10000 10000 10000 10000 10000 10000 10000 10000 10000 10000 10000 10000
				10000 10000 10000 10000 10000 10000 10000 10000 10000 10000 10000 10000 10000 10000 10000 10000 10000 10000
				10000 10000 10000 10000 10000 10000 10000 10000 10000 10000 10000 10000 10000 10000 10000 10000 10000 10000
				10000 10000 10000 10000 10000 10000 10000 10000 10000 10000 10000 10000 10000 10000 10000 10000 10000 10000
				>;

			PS_Config_Lmt_Open_Rawdata_P = <
				5120 5120 5120 5120 5120 5120 5120 5120 5120 5120 5120 5120 5120 5120 5120 5120 5120 5120
				5120 5120 5120 5120 5120 5120 5120 5120 5120 5120 5120 5120 5120 5120 5120 5120 5120 5120
				5120 5120 5120 5120 5120 5120 5120 5120 5120 5120 5120 5120 5120 5120 5120 5120 5120 5120
				5120 5120 5120 5120 5120 5120 5120 5120 5120 5120 5120 5120 5120 5120 5120 5120 5120 5120
				5120 5120 5120 5120 5120 5120 5120 5120 5120 5120 5120 5120 5120 5120 5120 5120 5120 5120
				5120 5120 5120 5120 5120 5120 5120 5120 5120 5120 5120 5120 5120 5120 5120 5120 5120 5120
				5120 5120 5120 5120 5120 5120 5120 5120 5120 5120 5120 5120 5120 5120 5120 5120 5120 5120
				5120 5120 5120 5120 5120 5120 5120 5120 5120 5120 5120 5120 5120 5120 5120 5120 5120 5120
				5120 5120 5120 5120 5120 5120 5120 5120 5120 5120 5120 5120 5120 5120 5120 5120 5120 5120
				5120 5120 5120 5120 5120 5120 5120 5120 5120 5120 5120 5120 5120 5120 5120 5120 5120 5120
				5120 5120 5120 5120 5120 5120 5120 5120 5120 5120 5120 5120 5120 5120 5120 5120 5120 5120
				5120 5120 5120 5120 5120 5120 5120 5120 5120 5120 5120 5120 5120 5120 5120 5120 5120 5120
				5120 5120 5120 5120 5120 5120 5120 5120 5120 5120 5120 5120 5120 5120 5120 5120 5120 5120
				5120 5120 5120 5120 5120 5120 5120 5120 5120 5120 5120 5120 5120 5120 5120 5120 5120 5120
				5120 5120 5120 5120 5120 5120 5120 5120 5120 5120 5120 5120 5120 5120 5120 5120 5120 5120
				5120 5120 5120 5120 5120 5120 5120 5120 5120 5120 5120 5120 5120 5120 5120 5120 5120 5120
				5120 5120 5120 5120 5120 5120 5120 5120 5120 5120 5120 5120 5120 5120 5120 5120 5120 5120
				5120 5120 5120 5120 5120 5120 5120 5120 5120 5120 5120 5120 5120 5120 5120 5120 5120 5120
				5120 5120 5120 5120 5120 5120 5120 5120 5120 5120 5120 5120 5120 5120 5120 5120 5120 5120
				5120 5120 5120 5120 5120 5120 5120 5120 5120 5120 5120 5120 5120 5120 5120 5120 5120 5120
				5120 5120 5120 5120 5120 5120 5120 5120 5120 5120 5120 5120 5120 5120 5120 5120 5120 5120
				5120 5120 5120 5120 5120 5120 5120 5120 5120 5120 5120 5120 5120 5120 5120 5120 5120 5120
				5120 5120 5120 5120 5120 5120 5120 5120 5120 5120 5120 5120 5120 5120 5120 5120 5120 5120
				5120 5120 5120 5120 5120 5120 5120 5120 5120 5120 5120 5120 5120 5120 5120 5120 5120 5120
				5120 5120 5120 5120 5120 5120 5120 5120 5120 5120 5120 5120 5120 5120 5120 5120 5120 5120
				5120 5120 5120 5120 5120 5120 5120 5120 5120 5120 5120 5120 5120 5120 5120 5120 5120 5120
				5120 5120 5120 5120 5120 5120 5120 5120 5120 5120 5120 5120 5120 5120 5120 5120 5120 5120
				5120 5120 5120 5120 5120 5120 5120 5120 5120 5120 5120 5120 5120 5120 5120 5120 5120 5120
				5120 5120 5120 5120 5120 5120 5120 5120 5120 5120 5120 5120 5120 5120 5120 5120 5120 5120
				5120 5120 5120 5120 5120 5120 5120 5120 5120 5120 5120 5120 5120 5120 5120 5120 5120 5120
				5120 5120 5120 5120 5120 5120 5120 5120 5120 5120 5120 5120 5120 5120 5120 5120 5120 5120
				5120 5120 5120 5120 5120 5120 5120 5120 5120 5120 5120 5120 5120 5120 5120 5120 5120 5120
				>;

			PS_Config_Lmt_Open_Rawdata_N = <
				(-511) (-511) (-511) (-511) (-511) (-511) (-511) (-511) (-511) (-511) (-511) (-511) (-511) (-511) (-511) (-511) (-511) (-511)
				(-511) (-511) (-511) (-511) (-511) (-511) (-511) (-511) (-511) (-511) (-511) (-511) (-511) (-511) (-511) (-511) (-511) (-511)
				(-511) (-511) (-511) (-511) (-511) (-511) (-511) (-511) (-511) (-511) (-511) (-511) (-511) (-511) (-511) (-511) (-511) (-511)
				(-511) (-511) (-511) (-511) (-511) (-511) (-511) (-511) (-511) (-511) (-511) (-511) (-511) (-511) (-511) (-511) (-511) (-511)
				(-511) (-511) (-511) (-511) (-511) (-511) (-511) (-511) (-511) (-511) (-511) (-511) (-511) (-511) (-511) (-511) (-511) (-511)
				(-511) (-511) (-511) (-511) (-511) (-511) (-511) (-511) (-511) (-511) (-511) (-511) (-511) (-511) (-511) (-511) (-511) (-511)
				(-511) (-511) (-511) (-511) (-511) (-511) (-511) (-511) (-511) (-511) (-511) (-511) (-511) (-511) (-511) (-511) (-511) (-511)
				(-511) (-511) (-511) (-511) (-511) (-511) (-511) (-511) (-511) (-511) (-511) (-511) (-511) (-511) (-511) (-511) (-511) (-511)
				(-511) (-511) (-511) (-511) (-511) (-511) (-511) (-511) (-511) (-511) (-511) (-511) (-511) (-511) (-511) (-511) (-511) (-511)
				(-511) (-511) (-511) (-511) (-511) (-511) (-511) (-511) (-511) (-511) (-511) (-511) (-511) (-511) (-511) (-511) (-511) (-511)
				(-511) (-511) (-511) (-511) (-511) (-511) (-511) (-511) (-511) (-511) (-511) (-511) (-511) (-511) (-511) (-511) (-511) (-511)
				(-511) (-511) (-511) (-511) (-511) (-511) (-511) (-511) (-511) (-511) (-511) (-511) (-511) (-511) (-511) (-511) (-511) (-511)
				(-511) (-511) (-511) (-511) (-511) (-511) (-511) (-511) (-511) (-511) (-511) (-511) (-511) (-511) (-511) (-511) (-511) (-511)
				(-511) (-511) (-511) (-511) (-511) (-511) (-511) (-511) (-511) (-511) (-511) (-511) (-511) (-511) (-511) (-511) (-511) (-511)
				(-511) (-511) (-511) (-511) (-511) (-511) (-511) (-511) (-511) (-511) (-511) (-511) (-511) (-511) (-511) (-511) (-511) (-511)
				(-511) (-511) (-511) (-511) (-511) (-511) (-511) (-511) (-511) (-511) (-511) (-511) (-511) (-511) (-511) (-511) (-511) (-511)
				(-511) (-511) (-511) (-511) (-511) (-511) (-511) (-511) (-511) (-511) (-511) (-511) (-511) (-511) (-511) (-511) (-511) (-511)
				(-511) (-511) (-511) (-511) (-511) (-511) (-511) (-511) (-511) (-511) (-511) (-511) (-511) (-511) (-511) (-511) (-511) (-511)
				(-511) (-511) (-511) (-511) (-511) (-511) (-511) (-511) (-511) (-511) (-511) (-511) (-511) (-511) (-511) (-511) (-511) (-511)
				(-511) (-511) (-511) (-511) (-511) (-511) (-511) (-511) (-511) (-511) (-511) (-511) (-511) (-511) (-511) (-511) (-511) (-511)
				(-511) (-511) (-511) (-511) (-511) (-511) (-511) (-511) (-511) (-511) (-511) (-511) (-511) (-511) (-511) (-511) (-511) (-511)
				(-511) (-511) (-511) (-511) (-511) (-511) (-511) (-511) (-511) (-511) (-511) (-511) (-511) (-511) (-511) (-511) (-511) (-511)
				(-511) (-511) (-511) (-511) (-511) (-511) (-511) (-511) (-511) (-511) (-511) (-511) (-511) (-511) (-511) (-511) (-511) (-511)
				(-511) (-511) (-511) (-511) (-511) (-511) (-511) (-511) (-511) (-511) (-511) (-511) (-511) (-511) (-511) (-511) (-511) (-511)
				(-511) (-511) (-511) (-511) (-511) (-511) (-511) (-511) (-511) (-511) (-511) (-511) (-511) (-511) (-511) (-511) (-511) (-511)
				(-511) (-511) (-511) (-511) (-511) (-511) (-511) (-511) (-511) (-511) (-511) (-511) (-511) (-511) (-511) (-511) (-511) (-511)
				(-511) (-511) (-511) (-511) (-511) (-511) (-511) (-511) (-511) (-511) (-511) (-511) (-511) (-511) (-511) (-511) (-511) (-511)
				(-511) (-511) (-511) (-511) (-511) (-511) (-511) (-511) (-511) (-511) (-511) (-511) (-511) (-511) (-511) (-511) (-511) (-511)
				(-511) (-511) (-511) (-511) (-511) (-511) (-511) (-511) (-511) (-511) (-511) (-511) (-511) (-511) (-511) (-511) (-511) (-511)
				(-511) (-511) (-511) (-511) (-511) (-511) (-511) (-511) (-511) (-511) (-511) (-511) (-511) (-511) (-511) (-511) (-511) (-511)
				(-511) (-511) (-511) (-511) (-511) (-511) (-511) (-511) (-511) (-511) (-511) (-511) (-511) (-511) (-511) (-511) (-511) (-511)
				(-511) (-511) (-511) (-511) (-511) (-511) (-511) (-511) (-511) (-511) (-511) (-511) (-511) (-511) (-511) (-511) (-511) (-511)
				>;

			PS_Config_Lmt_FW_Rawdata_P = <
				3840 3840 3840 3840 3840 3840 3840 3840 3840 3840 3840 3840 3840 3840 3840 3840 3840 3840
				3840 3840 3840 3840 3840 3840 3840 3840 3840 3840 3840 3840 3840 3840 3840 3840 3840 3840
				3840 3840 3840 3840 3840 3840 3840 3840 3840 3840 3840 3840 3840 3840 3840 3840 3840 3840
				3840 3840 3840 3840 3840 3840 3840 3840 3840 3840 3840 3840 3840 3840 3840 3840 3840 3840
				3840 3840 3840 3840 3840 3840 3840 3840 3840 3840 3840 3840 3840 3840 3840 3840 3840 3840
				3840 3840 3840 3840 3840 3840 3840 3840 3840 3840 3840 3840 3840 3840 3840 3840 3840 3840
				3840 3840 3840 3840 3840 3840 3840 3840 3840 3840 3840 3840 3840 3840 3840 3840 3840 3840
				3840 3840 3840 3840 3840 3840 3840 3840 3840 3840 3840 3840 3840 3840 3840 3840 3840 3840
				3840 3840 3840 3840 3840 3840 3840 3840 3840 3840 3840 3840 3840 3840 3840 3840 3840 3840
				3840 3840 3840 3840 3840 3840 3840 3840 3840 3840 3840 3840 3840 3840 3840 3840 3840 3840
				3840 3840 3840 3840 3840 3840 3840 3840 3840 3840 3840 3840 3840 3840 3840 3840 3840 3840
				3840 3840 3840 3840 3840 3840 3840 3840 3840 3840 3840 3840 3840 3840 3840 3840 3840 3840
				3840 3840 3840 3840 3840 3840 3840 3840 3840 3840 3840 3840 3840 3840 3840 3840 3840 3840
				3840 3840 3840 3840 3840 3840 3840 3840 3840 3840 3840 3840 3840 3840 3840 3840 3840 3840
				3840 3840 3840 3840 3840 3840 3840 3840 3840 3840 3840 3840 3840 3840 3840 3840 3840 3840
				3840 3840 3840 3840 3840 3840 3840 3840 3840 3840 3840 3840 3840 3840 3840 3840 3840 3840
				3840 3840 3840 3840 3840 3840 3840 3840 3840 3840 3840 3840 3840 3840 3840 3840 3840 3840
				3840 3840 3840 3840 3840 3840 3840 3840 3840 3840 3840 3840 3840 3840 3840 3840 3840 3840
				3840 3840 3840 3840 3840 3840 3840 3840 3840 3840 3840 3840 3840 3840 3840 3840 3840 3840
				3840 3840 3840 3840 3840 3840 3840 3840 3840 3840 3840 3840 3840 3840 3840 3840 3840 3840
				3840 3840 3840 3840 3840 3840 3840 3840 3840 3840 3840 3840 3840 3840 3840 3840 3840 3840
				3840 3840 3840 3840 3840 3840 3840 3840 3840 3840 3840 3840 3840 3840 3840 3840 3840 3840
				3840 3840 3840 3840 3840 3840 3840 3840 3840 3840 3840 3840 3840 3840 3840 3840 3840 3840
				3840 3840 3840 3840 3840 3840 3840 3840 3840 3840 3840 3840 3840 3840 3840 3840 3840 3840
				3840 3840 3840 3840 3840 3840 3840 3840 3840 3840 3840 3840 3840 3840 3840 3840 3840 3840
				3840 3840 3840 3840 3840 3840 3840 3840 3840 3840 3840 3840 3840 3840 3840 3840 3840 3840
				3840 3840 3840 3840 3840 3840 3840 3840 3840 3840 3840 3840 3840 3840 3840 3840 3840 3840
				3840 3840 3840 3840 3840 3840 3840 3840 3840 3840 3840 3840 3840 3840 3840 3840 3840 3840
				3840 3840 3840 3840 3840 3840 3840 3840 3840 3840 3840 3840 3840 3840 3840 3840 3840 3840
				3840 3840 3840 3840 3840 3840 3840 3840 3840 3840 3840 3840 3840 3840 3840 3840 3840 3840
				3840 3840 3840 3840 3840 3840 3840 3840 3840 3840 3840 3840 3840 3840 3840 3840 3840 3840
				3840 3840 3840 3840 3840 3840 3840 3840 3840 3840 3840 3840 3840 3840 3840 3840 3840 3840
				>;

			PS_Config_Lmt_FW_Rawdata_N = <
				240 240 240 240 240 240 240 240 240 240 240 240 240 240 240 240 240 240
				240 240 240 240 240 240 240 240 240 240 240 240 240 240 240 240 240 240
				240 240 240 240 240 240 240 240 240 240 240 240 240 240 240 240 240 240
				240 240 240 240 240 240 240 240 240 240 240 240 240 240 240 240 240 240
				240 240 240 240 240 240 240 240 240 240 240 240 240 240 240 240 240 240
				240 240 240 240 240 240 240 240 240 240 240 240 240 240 240 240 240 240
				240 240 240 240 240 240 240 240 240 240 240 240 240 240 240 240 240 240
				240 240 240 240 240 240 240 240 240 240 240 240 240 240 240 240 240 240
				240 240 240 240 240 240 240 240 240 240 240 240 240 240 240 240 240 240
				240 240 240 240 240 240 240 240 240 240 240 240 240 240 240 240 240 240
				240 240 240 240 240 240 240 240 240 240 240 240 240 240 240 240 240 240
				240 240 240 240 240 240 240 240 240 240 240 240 240 240 240 240 240 240
				240 240 240 240 240 240 240 240 240 240 240 240 240 240 240 240 240 240
				240 240 240 240 240 240 240 240 240 240 240 240 240 240 240 240 240 240
				240 240 240 240 240 240 240 240 240 240 240 240 240 240 240 240 240 240
				240 240 240 240 240 240 240 240 240 240 240 240 240 240 240 240 240 240
				240 240 240 240 240 240 240 240 240 240 240 240 240 240 240 240 240 240
				240 240 240 240 240 240 240 240 240 240 240 240 240 240 240 240 240 240
				240 240 240 240 240 240 240 240 240 240 240 240 240 240 240 240 240 240
				240 240 240 240 240 240 240 240 240 240 240 240 240 240 240 240 240 240
				240 240 240 240 240 240 240 240 240 240 240 240 240 240 240 240 240 240
				240 240 240 240 240 240 240 240 240 240 240 240 240 240 240 240 240 240
				240 240 240 240 240 240 240 240 240 240 240 240 240 240 240 240 240 240
				240 240 240 240 240 240 240 240 240 240 240 240 240 240 240 240 240 240
				240 240 240 240 240 240 240 240 240 240 240 240 240 240 240 240 240 240
				240 240 240 240 240 240 240 240 240 240 240 240 240 240 240 240 240 240
				240 240 240 240 240 240 240 240 240 240 240 240 240 240 240 240 240 240
				240 240 240 240 240 240 240 240 240 240 240 240 240 240 240 240 240 240
				240 240 240 240 240 240 240 240 240 240 240 240 240 240 240 240 240 240
				240 240 240 240 240 240 240 240 240 240 240 240 240 240 240 240 240 240
				240 240 240 240 240 240 240 240 240 240 240 240 240 240 240 240 240 240
				240 240 240 240 240 240 240 240 240 240 240 240 240 240 240 240 240 240
				>;

			PS_Config_Lmt_FW_CC_P = <
				314 314 314 314 314 314 314 314 314 314 314 314 314 314 314 314 314 314
				314 314 314 314 314 314 314 314 314 314 314 314 314 314 314 314 314 314
				314 314 314 314 314 314 314 314 314 314 314 314 314 314 314 314 314 314
				314 314 314 314 314 314 314 314 314 314 314 314 314 314 314 314 314 314
				314 314 314 314 314 314 314 314 314 314 314 314 314 314 314 314 314 314
				314 314 314 314 314 314 314 314 314 314 314 314 314 314 314 314 314 314
				314 314 314 314 314 314 314 314 314 314 314 314 314 314 314 314 314 314
				314 314 314 314 314 314 314 314 314 314 314 314 314 314 314 314 314 314
				314 314 314 314 314 314 314 314 314 314 314 314 314 314 314 314 314 314
				314 314 314 314 314 314 314 314 314 314 314 314 314 314 314 314 314 314
				314 314 314 314 314 314 314 314 314 314 314 314 314 314 314 314 314 314
				314 314 314 314 314 314 314 314 314 314 314 314 314 314 314 314 314 314
				314 314 314 314 314 314 314 314 314 314 314 314 314 314 314 314 314 314
				314 314 314 314 314 314 314 314 314 314 314 314 314 314 314 314 314 314
				314 314 314 314 314 314 314 314 314 314 314 314 314 314 314 314 314 314
				314 314 314 314 314 314 314 314 314 314 314 314 314 314 314 314 314 314
				314 314 314 314 314 314 314 314 314 314 314 314 314 314 314 314 314 314
				314 314 314 314 314 314 314 314 314 314 314 314 314 314 314 314 314 314
				314 314 314 314 314 314 314 314 314 314 314 314 314 314 314 314 314 314
				314 314 314 314 314 314 314 314 314 314 314 314 314 314 314 314 314 314
				314 314 314 314 314 314 314 314 314 314 314 314 314 314 314 314 314 314
				314 314 314 314 314 314 314 314 314 314 314 314 314 314 314 314 314 314
				314 314 314 314 314 314 314 314 314 314 314 314 314 314 314 314 314 314
				314 314 314 314 314 314 314 314 314 314 314 314 314 314 314 314 314 314
				314 314 314 314 314 314 314 314 314 314 314 314 314 314 314 314 314 314
				314 314 314 314 314 314 314 314 314 314 314 314 314 314 314 314 314 314
				314 314 314 314 314 314 314 314 314 314 314 314 314 314 314 314 314 314
				314 314 314 314 314 314 314 314 314 314 314 314 314 314 314 314 314 314
				314 314 314 314 314 314 314 314 314 314 314 314 314 314 314 314 314 314
				314 314 314 314 314 314 314 314 314 314 314 314 314 314 314 314 314 314
				314 314 314 314 314 314 314 314 314 314 314 314 314 314 314 314 314 314
				314 314 314 314 314 314 314 314 314 314 314 314 314 314 314 314 314 314
				>;

			PS_Config_Lmt_FW_CC_N = <
				0 0 0 0 0 0 0 0 0 0 0 0 0 0 0 0 0 0
				0 0 0 0 0 0 0 0 0 0 0 0 0 0 0 0 0 0
				0 0 0 0 0 0 0 0 0 0 0 0 0 0 0 0 0 0
				0 0 0 0 0 0 0 0 0 0 0 0 0 0 0 0 0 0
				0 0 0 0 0 0 0 0 0 0 0 0 0 0 0 0 0 0
				0 0 0 0 0 0 0 0 0 0 0 0 0 0 0 0 0 0
				0 0 0 0 0 0 0 0 0 0 0 0 0 0 0 0 0 0
				0 0 0 0 0 0 0 0 0 0 0 0 0 0 0 0 0 0
				0 0 0 0 0 0 0 0 0 0 0 0 0 0 0 0 0 0
				0 0 0 0 0 0 0 0 0 0 0 0 0 0 0 0 0 0
				0 0 0 0 0 0 0 0 0 0 0 0 0 0 0 0 0 0
				0 0 0 0 0 0 0 0 0 0 0 0 0 0 0 0 0 0
				0 0 0 0 0 0 0 0 0 0 0 0 0 0 0 0 0 0
				0 0 0 0 0 0 0 0 0 0 0 0 0 0 0 0 0 0
				0 0 0 0 0 0 0 0 0 0 0 0 0 0 0 0 0 0
				0 0 0 0 0 0 0 0 0 0 0 0 0 0 0 0 0 0
				0 0 0 0 0 0 0 0 0 0 0 0 0 0 0 0 0 0
				0 0 0 0 0 0 0 0 0 0 0 0 0 0 0 0 0 0
				0 0 0 0 0 0 0 0 0 0 0 0 0 0 0 0 0 0
				0 0 0 0 0 0 0 0 0 0 0 0 0 0 0 0 0 0
				0 0 0 0 0 0 0 0 0 0 0 0 0 0 0 0 0 0
				0 0 0 0 0 0 0 0 0 0 0 0 0 0 0 0 0 0
				0 0 0 0 0 0 0 0 0 0 0 0 0 0 0 0 0 0
				0 0 0 0 0 0 0 0 0 0 0 0 0 0 0 0 0 0
				0 0 0 0 0 0 0 0 0 0 0 0 0 0 0 0 0 0
				0 0 0 0 0 0 0 0 0 0 0 0 0 0 0 0 0 0
				0 0 0 0 0 0 0 0 0 0 0 0 0 0 0 0 0 0
				0 0 0 0 0 0 0 0 0 0 0 0 0 0 0 0 0 0
				0 0 0 0 0 0 0 0 0 0 0 0 0 0 0 0 0 0
				0 0 0 0 0 0 0 0 0 0 0 0 0 0 0 0 0 0
				0 0 0 0 0 0 0 0 0 0 0 0 0 0 0 0 0 0
				0 0 0 0 0 0 0 0 0 0 0 0 0 0 0 0 0 0
				>;

			PS_Config_Lmt_FW_Diff_P = <
				75 75 75 75 75 75 75 75 75 75 75 75 75 75 75 75 75 75
				75 75 75 75 75 75 75 75 75 75 75 75 75 75 75 75 75 75
				75 75 75 75 75 75 75 75 75 75 75 75 75 75 75 75 75 75
				75 75 75 75 75 75 75 75 75 75 75 75 75 75 75 75 75 75
				75 75 75 75 75 75 75 75 75 75 75 75 75 75 75 75 75 75
				75 75 75 75 75 75 75 75 75 75 75 75 75 75 75 75 75 75
				75 75 75 75 75 75 75 75 75 75 75 75 75 75 75 75 75 75
				75 75 75 75 75 75 75 75 75 75 75 75 75 75 75 75 75 75
				75 75 75 75 75 75 75 75 75 75 75 75 75 75 75 75 75 75
				75 75 75 75 75 75 75 75 75 75 75 75 75 75 75 75 75 75
				75 75 75 75 75 75 75 75 75 75 75 75 75 75 75 75 75 75
				75 75 75 75 75 75 75 75 75 75 75 75 75 75 75 75 75 75
				75 75 75 75 75 75 75 75 75 75 75 75 75 75 75 75 75 75
				75 75 75 75 75 75 75 75 75 75 75 75 75 75 75 75 75 75
				75 75 75 75 75 75 75 75 75 75 75 75 75 75 75 75 75 75
				75 75 75 75 75 75 75 75 75 75 75 75 75 75 75 75 75 75
				75 75 75 75 75 75 75 75 75 75 75 75 75 75 75 75 75 75
				75 75 75 75 75 75 75 75 75 75 75 75 75 75 75 75 75 75
				75 75 75 75 75 75 75 75 75 75 75 75 75 75 75 75 75 75
				75 75 75 75 75 75 75 75 75 75 75 75 75 75 75 75 75 75
				75 75 75 75 75 75 75 75 75 75 75 75 75 75 75 75 75 75
				75 75 75 75 75 75 75 75 75 75 75 75 75 75 75 75 75 75
				75 75 75 75 75 75 75 75 75 75 75 75 75 75 75 75 75 75
				75 75 75 75 75 75 75 75 75 75 75 75 75 75 75 75 75 75
				75 75 75 75 75 75 75 75 75 75 75 75 75 75 75 75 75 75
				75 75 75 75 75 75 75 75 75 75 75 75 75 75 75 75 75 75
				75 75 75 75 75 75 75 75 75 75 75 75 75 75 75 75 75 75
				75 75 75 75 75 75 75 75 75 75 75 75 75 75 75 75 75 75
				75 75 75 75 75 75 75 75 75 75 75 75 75 75 75 75 75 75
				75 75 75 75 75 75 75 75 75 75 75 75 75 75 75 75 75 75
				75 75 75 75 75 75 75 75 75 75 75 75 75 75 75 75 75 75
				75 75 75 75 75 75 75 75 75 75 75 75 75 75 75 75 75 75
				>;

			PS_Config_Lmt_FW_Diff_N = <
				(-75) (-75) (-75) (-75) (-75) (-75) (-75) (-75) (-75) (-75) (-75) (-75) (-75) (-75) (-75) (-75) (-75) (-75)
				(-75) (-75) (-75) (-75) (-75) (-75) (-75) (-75) (-75) (-75) (-75) (-75) (-75) (-75) (-75) (-75) (-75) (-75)
				(-75) (-75) (-75) (-75) (-75) (-75) (-75) (-75) (-75) (-75) (-75) (-75) (-75) (-75) (-75) (-75) (-75) (-75)
				(-75) (-75) (-75) (-75) (-75) (-75) (-75) (-75) (-75) (-75) (-75) (-75) (-75) (-75) (-75) (-75) (-75) (-75)
				(-75) (-75) (-75) (-75) (-75) (-75) (-75) (-75) (-75) (-75) (-75) (-75) (-75) (-75) (-75) (-75) (-75) (-75)
				(-75) (-75) (-75) (-75) (-75) (-75) (-75) (-75) (-75) (-75) (-75) (-75) (-75) (-75) (-75) (-75) (-75) (-75)
				(-75) (-75) (-75) (-75) (-75) (-75) (-75) (-75) (-75) (-75) (-75) (-75) (-75) (-75) (-75) (-75) (-75) (-75)
				(-75) (-75) (-75) (-75) (-75) (-75) (-75) (-75) (-75) (-75) (-75) (-75) (-75) (-75) (-75) (-75) (-75) (-75)
				(-75) (-75) (-75) (-75) (-75) (-75) (-75) (-75) (-75) (-75) (-75) (-75) (-75) (-75) (-75) (-75) (-75) (-75)
				(-75) (-75) (-75) (-75) (-75) (-75) (-75) (-75) (-75) (-75) (-75) (-75) (-75) (-75) (-75) (-75) (-75) (-75)
				(-75) (-75) (-75) (-75) (-75) (-75) (-75) (-75) (-75) (-75) (-75) (-75) (-75) (-75) (-75) (-75) (-75) (-75)
				(-75) (-75) (-75) (-75) (-75) (-75) (-75) (-75) (-75) (-75) (-75) (-75) (-75) (-75) (-75) (-75) (-75) (-75)
				(-75) (-75) (-75) (-75) (-75) (-75) (-75) (-75) (-75) (-75) (-75) (-75) (-75) (-75) (-75) (-75) (-75) (-75)
				(-75) (-75) (-75) (-75) (-75) (-75) (-75) (-75) (-75) (-75) (-75) (-75) (-75) (-75) (-75) (-75) (-75) (-75)
				(-75) (-75) (-75) (-75) (-75) (-75) (-75) (-75) (-75) (-75) (-75) (-75) (-75) (-75) (-75) (-75) (-75) (-75)
				(-75) (-75) (-75) (-75) (-75) (-75) (-75) (-75) (-75) (-75) (-75) (-75) (-75) (-75) (-75) (-75) (-75) (-75)
				(-75) (-75) (-75) (-75) (-75) (-75) (-75) (-75) (-75) (-75) (-75) (-75) (-75) (-75) (-75) (-75) (-75) (-75)
				(-75) (-75) (-75) (-75) (-75) (-75) (-75) (-75) (-75) (-75) (-75) (-75) (-75) (-75) (-75) (-75) (-75) (-75)
				(-75) (-75) (-75) (-75) (-75) (-75) (-75) (-75) (-75) (-75) (-75) (-75) (-75) (-75) (-75) (-75) (-75) (-75)
				(-75) (-75) (-75) (-75) (-75) (-75) (-75) (-75) (-75) (-75) (-75) (-75) (-75) (-75) (-75) (-75) (-75) (-75)
				(-75) (-75) (-75) (-75) (-75) (-75) (-75) (-75) (-75) (-75) (-75) (-75) (-75) (-75) (-75) (-75) (-75) (-75)
				(-75) (-75) (-75) (-75) (-75) (-75) (-75) (-75) (-75) (-75) (-75) (-75) (-75) (-75) (-75) (-75) (-75) (-75)
				(-75) (-75) (-75) (-75) (-75) (-75) (-75) (-75) (-75) (-75) (-75) (-75) (-75) (-75) (-75) (-75) (-75) (-75)
				(-75) (-75) (-75) (-75) (-75) (-75) (-75) (-75) (-75) (-75) (-75) (-75) (-75) (-75) (-75) (-75) (-75) (-75)
				(-75) (-75) (-75) (-75) (-75) (-75) (-75) (-75) (-75) (-75) (-75) (-75) (-75) (-75) (-75) (-75) (-75) (-75)
				(-75) (-75) (-75) (-75) (-75) (-75) (-75) (-75) (-75) (-75) (-75) (-75) (-75) (-75) (-75) (-75) (-75) (-75)
				(-75) (-75) (-75) (-75) (-75) (-75) (-75) (-75) (-75) (-75) (-75) (-75) (-75) (-75) (-75) (-75) (-75) (-75)
				(-75) (-75) (-75) (-75) (-75) (-75) (-75) (-75) (-75) (-75) (-75) (-75) (-75) (-75) (-75) (-75) (-75) (-75)
				(-75) (-75) (-75) (-75) (-75) (-75) (-75) (-75) (-75) (-75) (-75) (-75) (-75) (-75) (-75) (-75) (-75) (-75)
				(-75) (-75) (-75) (-75) (-75) (-75) (-75) (-75) (-75) (-75) (-75) (-75) (-75) (-75) (-75) (-75) (-75) (-75)
				(-75) (-75) (-75) (-75) (-75) (-75) (-75) (-75) (-75) (-75) (-75) (-75) (-75) (-75) (-75) (-75) (-75) (-75)
				(-75) (-75) (-75) (-75) (-75) (-75) (-75) (-75) (-75) (-75) (-75) (-75) (-75) (-75) (-75) (-75) (-75) (-75)
				>;

			PS_Config_Diff_Test_Frame = <50>;
		};
	};
};

&pio {
	nvt_pins_eint_as_int: eint1touch@0 {
		pins_cmd_dat {
			pinmux = <PINMUX_GPIO14__FUNC_GPIO14>;
			input-enable;
		};
	};
	nvt_pins_rst_output: rstoutput0 {
		pins_cmd_dat {
			pinmux = <PINMUX_GPIO15__FUNC_GPIO15>;
			output-low;
		};
	};
	nvt_spi_mode: spimode_default {
		pins_cmd_dat {
			pinmux = <PINMUX_GPIO12__FUNC_SPI4_MI>,
				<PINMUX_GPIO13__FUNC_SPI4_MO>,
				<PINMUX_GPIO97__FUNC_SPI4_CLK>,
				<PINMUX_GPIO98__FUNC_SPI4_CSB>;
			drive-strength = <6>;
		};
	};
};
